# USCI_A0__SPI_Mode_3 register map
Vendor: Texas Instruments
Peripheral module from a debugger description file (folder msp430).
Registers are 8-bit, access not given, no defined reset value unless marked. A register's access mark holds for its fields unless they carry their own. Offsets are as the file gives them; lines under a group give offsets from that group; [hi:lo] are bit positions; {n}, {i} and the like mark numbered series; 'fields as' and 'values as' point back to an identical list; <NAME> marks a mode.

## USCI_A0_SPI_Mode
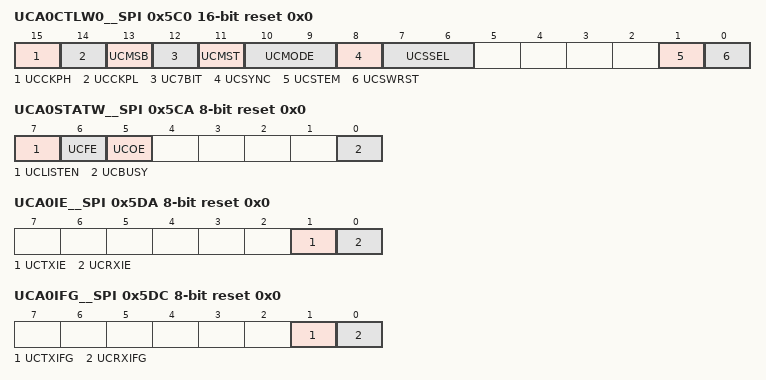
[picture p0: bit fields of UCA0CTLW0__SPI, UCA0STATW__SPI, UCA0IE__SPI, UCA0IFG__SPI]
0x5C0 UCA0CTLW0__SPI 16-bit rw reset 0x0 — USCI A0 Control Word Register 0
  [15] UCCKPH — Sync. Mode: Clock Phase
  [14] UCCKPL — Sync. Mode: Clock Polarity
  [13] UCMSB — Sync. Mode: MSB first 0:LSB / 1:MSB
  [12] UC7BIT — Sync. Mode: Data Bits 0:8-bits / 1:7-bits
  [11] UCMST — Sync. Mode: Master Select
  [10:9] UCMODE — Sync. Mode: USCI Mode 1
    {v}=Sync. Mode: USCI Mode: {v} (v=0..3)
  [8] UCSYNC — Sync-Mode 0:UART-Mode / 1:SPI-Mode
  [7:6] UCSSEL — USCI 1 Clock Source Select 1
    {v}=USCI 0 Clock Source: {v} (v=0..3)
  [1] UCSTEM — USCI STE Mode
  [0] UCSWRST — USCI Software Reset
0x5C0 UCA0CTL1__SPI — USCI A0 Control Register 1
0x5C1 UCA0CTL0__SPI — USCI A0 Control Register 0
0x5C6 UCA0BRW__SPI 16-bit — USCI A0 Baud Word Rate 0
0x5C6 UCA0BR0__SPI — USCI A0 Baud Rate 0
0x5C7 UCA0BR1__SPI — USCI A0 Baud Rate 1
0x5CA UCA0STATW__SPI rw reset 0x0 — USCI A0 Status Register
  [7] UCLISTEN — USCI Listen mode
  [6] UCFE — USCI Frame Error Flag
  [5] UCOE — USCI Overrun Error Flag
  [0] UCBUSY — USCI Busy Flag
0x5CC UCA0RXBUF__SPI 16-bit — USCI A0 Receive Buffer
0x5CE UCA0TXBUF__SPI 16-bit — USCI A0 Transmit Buffer
0x5DA UCA0IE__SPI rw reset 0x0 — USCI A0 Interrupt Enable Register
  [1] UCTXIE — USCI Transmit Interrupt Enable
  [0] UCRXIE — USCI Receive Interrupt Enable
0x5DC UCA0IFG__SPI rw reset 0x0 — USCI A0 Interrupt Flags Register
  [1] UCTXIFG — SPI Transmit Interrupt Flag
  [0] UCRXIFG — SPI Receive Interrupt Flag
0x5DE UCA0IV__SPI 16-bit — USCI A0 Interrupt Vector Register
